VERSION ""

NS_ :

BS_:

BU_: XXX

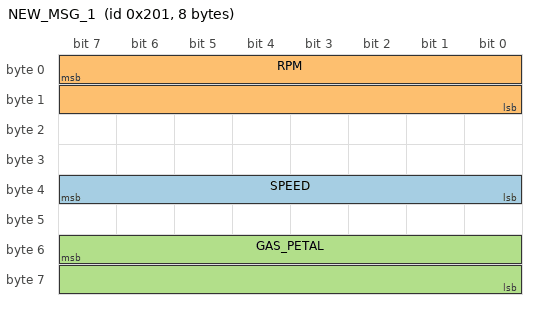
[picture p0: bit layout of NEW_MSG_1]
BO_ 513 NEW_MSG_1: 8 XXX
 SG_ SPEED : 39|8@0+ (1,0) [0|255] "" XXX
 SG_ RPM : 7|16@0+ (1,0) [0|65535] "" XXX
 SG_ GAS_PETAL : 55|16@0+ (1,0) [0|65535] "" XXX

BO_ 128 NEW_MSG_2: 8 XXX
 SG_ STEERING_ANGLE : 7|16@0+ (1,0) [0|65535] "" XXX

BO_TX_BU_ 513 : NEW_TRANSMITTER_1;
